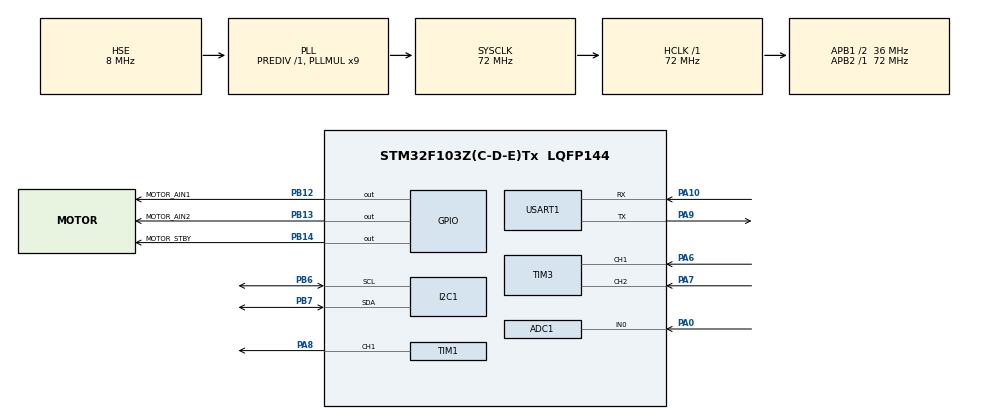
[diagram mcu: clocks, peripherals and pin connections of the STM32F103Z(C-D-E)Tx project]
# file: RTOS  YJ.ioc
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ADC1.Channel-0\#ChannelRegularConversion=ADC_CHANNEL_0
ADC1.ContinuousConvMode=ENABLE
ADC1.NbrOfConversionFlag=1
ADC1.Rank-0\#ChannelRegularConversion=1
ADC1.SamplingTime-0\#ChannelRegularConversion=ADC_SAMPLETIME_1CYCLE_5
ADC1.master=1
Dma.Request0=USART1_TX
Dma.Request1=USART1_RX
Dma.USART1_RX.1.Direction=DMA_PERIPH_TO_MEMORY
Dma.USART1_RX.1.Instance=DMA1_Channel5
Dma.USART1_RX.1.MemDataAlignment=DMA_MDATAALIGN_BYTE
Dma.USART1_RX.1.MemInc=DMA_MINC_ENABLE
Dma.USART1_RX.1.Mode=DMA_CIRCULAR
Dma.USART1_RX.1.PeriphDataAlignment=DMA_PDATAALIGN_BYTE
Dma.USART1_RX.1.PeriphInc=DMA_PINC_DISABLE
Dma.USART1_RX.1.Priority=DMA_PRIORITY_LOW
Dma.USART1_TX.0.Direction=DMA_MEMORY_TO_PERIPH
Dma.USART1_TX.0.Instance=DMA1_Channel4
Dma.USART1_TX.0.MemDataAlignment=DMA_MDATAALIGN_BYTE
Dma.USART1_TX.0.MemInc=DMA_MINC_ENABLE
Dma.USART1_TX.0.Mode=DMA_NORMAL
Dma.USART1_TX.0.PeriphDataAlignment=DMA_PDATAALIGN_BYTE
Dma.USART1_TX.0.PeriphInc=DMA_PINC_DISABLE
Dma.USART1_TX.0.Priority=DMA_PRIORITY_LOW
FREERTOS.Tasks01=defaultTask,0,128,StartDefaultTask,Default,NULL,Dynamic,NULL,NULL
FREERTOS.configCHECK_FOR_STACK_OVERFLOW=2
FREERTOS.configLIBRARY_MAX_SYSCALL_INTERRUPT_PRIORITY=6
FREERTOS.configMAX_PRIORITIES=8
FREERTOS.configTOTAL_HEAP_SIZE=16384
FREERTOS.configUSE_COUNTING_SEMAPHORES=1
I2C1.I2C_Mode=I2C_Fast
Mcu.Family=STM32F1
Mcu.Name=STM32F103Z(C-D-E)Tx
Mcu.Package=LQFP144
NVIC.DMA1_Channel4_IRQn=true\:6\:0\:true\:false\:true\:true\:false\:true\:true
NVIC.DMA1_Channel5_IRQn=true\:6\:0\:true\:false\:true\:true\:false\:true\:true
NVIC.PriorityGroup=NVIC_PRIORITYGROUP_4
NVIC.TIM2_IRQn=true\:6\:0\:true\:false\:true\:true\:true\:true\:true
NVIC.TIM4_IRQn=true\:15\:0\:false\:false\:true\:false\:false\:true\:true
NVIC.TimeBase=TIM4_IRQn
NVIC.TimeBaseIP=TIM4
NVIC.USART1_IRQn=true\:6\:0\:true\:false\:true\:true\:false\:true\:true
OSC_IN.Mode=HSE-External-Oscillator
OSC_IN.Signal=RCC_OSC_IN
OSC_OUT.Mode=HSE-External-Oscillator
OSC_OUT.Signal=RCC_OSC_OUT
PA0-WKUP.Signal=ADCx_IN0
PA10.Mode=Asynchronous
PA10.Signal=USART1_RX
PA13.Mode=Serial_Wire
PA13.Signal=SYS_JTMS-SWDIO
PA14.Mode=Serial_Wire
PA14.Signal=SYS_JTCK-SWCLK
PA6.Signal=S_TIM3_CH1
PA7.Signal=S_TIM3_CH2
PA8.Signal=S_TIM1_CH1
PA9.Mode=Asynchronous
PA9.Signal=USART1_TX
PB12.GPIO_Label=MOTOR_AIN1
PB12.Signal=GPIO_Output
PB13.GPIO_Label=MOTOR_AIN2
PB13.Signal=GPIO_Output
PB14.GPIO_Label=MOTOR_STBY
PB14.Signal=GPIO_Output
PB6.Mode=I2C
PB6.Signal=I2C1_SCL
PB7.Mode=I2C
PB7.Signal=I2C1_SDA
PC14-OSC32_IN.Mode=LSE-External-Oscillator
PC14-OSC32_IN.Signal=RCC_OSC32_IN
PC15-OSC32_OUT.Mode=LSE-External-Oscillator
PC15-OSC32_OUT.Signal=RCC_OSC32_OUT
ProjectManager.HeapSize=0x200
ProjectManager.StackSize=0x400
ProjectManager.TargetToolchain=MDK-ARM V5.32
RCC.ADCPresc=RCC_ADCPCLK2_DIV6
RCC.AHBFreq_Value=72000000
RCC.APB1CLKDivider=RCC_HCLK_DIV2
RCC.APB1Freq_Value=36000000
RCC.APB1TimFreq_Value=72000000
RCC.APB2Freq_Value=72000000
RCC.APB2TimFreq_Value=72000000
RCC.HCLKFreq_Value=72000000
RCC.PLLMUL=RCC_PLL_MUL9
RCC.PLLSourceVirtual=RCC_PLLSOURCE_HSE
RCC.SYSCLKFreq_VALUE=72000000
RCC.SYSCLKSource=RCC_SYSCLKSOURCE_PLLCLK
RCC.USBFreq_Value=72000000
SH.ADCx_IN0.0=ADC1_IN0,IN0
SH.S_TIM1_CH1.0=TIM1_CH1,PWM Generation1 CH1
SH.S_TIM3_CH1.0=TIM3_CH1,Encoder_Interface
SH.S_TIM3_CH2.0=TIM3_CH2,Encoder_Interface
TIM1.Channel-PWM\ Generation1\ CH1=TIM_CHANNEL_1
TIM1.Period=999
TIM1.Prescaler=3
TIM2.Period=999
TIM2.Prescaler=71
TIM3.EncoderMode=TIM_ENCODERMODE_TI12
USART1.VirtualMode=VM_ASYNC
VP_FREERTOS_VS_CMSIS_V1.Mode=CMSIS_V1
VP_SYS_VS_tim4.Mode=TIM4
VP_TIM2_VS_ClockSourceINT.Mode=Internal
board=custom

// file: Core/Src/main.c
/* USER CODE BEGIN Header */
/**
  ******************************************************************************
  * @file           : main.c
  * @brief          : Main program body
  ******************************************************************************
  * @attention
  *
  * Copyright (c) 2026 STMicroelectronics.
  * All rights reserved.
  *
  * This software is licensed under terms that can be found in the LICENSE file
  * in the root directory of this software component.
  * If no LICENSE file comes with this software, it is provided AS-IS.
  *
  ******************************************************************************
  */
/* USER CODE END Header */
#include "main.h"
#include "FreeRTOS.h"
#include "task.h"
#include "cmsis_os.h"
#include "tasks.h"
#include "uart_dma.h"
#include "adc.h"
#include "dma.h"
#include "i2c.h"
#include "tim.h"
#include "usart.h"
#include "gpio.h"

void SystemClock_Config(void);
/* USER CODE BEGIN PFP */
void MX_FREERTOS_Init(void);
/* USER CODE END PFP */

int main(void)
{

  /* MCU Configuration--------------------------------------------------------*/

  /* Reset of all peripherals, Initializes the Flash interface and the Systick. */
  HAL_Init();

  /* Configure the system clock */
  SystemClock_Config();

  /* Initialize all configured peripherals */
  MX_GPIO_Init();
  MX_DMA_Init();
  MX_USART1_UART_Init();
  MX_ADC1_Init();
  MX_I2C1_Init();
  MX_TIM1_Init();
  MX_TIM2_Init();
  MX_TIM3_Init();
  /* USER CODE BEGIN 2 */
  uart_dma_init();
  /* USER CODE END 2 */

  /* Init FreeRTOS (creates the tasks) */
  MX_FREERTOS_Init();

  /* Start the scheduler (never returns) */
  osKernelStart();

  /* We should never get here as control is now taken by the scheduler */

  /* Infinite loop */
  while (1)
  {

  }
}

void SystemClock_Config(void)
{
  RCC_OscInitTypeDef RCC_OscInitStruct = {0};
  RCC_ClkInitTypeDef RCC_ClkInitStruct = {0};
  RCC_PeriphCLKInitTypeDef PeriphClkInit = {0};

  /** Initializes the RCC Oscillators according to the specified parameters
  * in the RCC_OscInitTypeDef structure.
  */
  RCC_OscInitStruct.OscillatorType = RCC_OSCILLATORTYPE_HSE;
  RCC_OscInitStruct.HSEState = RCC_HSE_ON;
  RCC_OscInitStruct.HSEPredivValue = RCC_HSE_PREDIV_DIV1;
  RCC_OscInitStruct.HSIState = RCC_HSI_ON;
  RCC_OscInitStruct.PLL.PLLState = RCC_PLL_ON;
  RCC_OscInitStruct.PLL.PLLSource = RCC_PLLSOURCE_HSE;
  RCC_OscInitStruct.PLL.PLLMUL = RCC_PLL_MUL9;
  if (HAL_RCC_OscConfig(&RCC_OscInitStruct) != HAL_OK)
  {
    Error_Handler();
  }

  /** Initializes the CPU, AHB and APB buses clocks
  */
  RCC_ClkInitStruct.ClockType = RCC_CLOCKTYPE_HCLK|RCC_CLOCKTYPE_SYSCLK
                              |RCC_CLOCKTYPE_PCLK1|RCC_CLOCKTYPE_PCLK2;
  RCC_ClkInitStruct.SYSCLKSource = RCC_SYSCLKSOURCE_PLLCLK;
  RCC_ClkInitStruct.AHBCLKDivider = RCC_SYSCLK_DIV1;
  RCC_ClkInitStruct.APB1CLKDivider = RCC_HCLK_DIV2;
  RCC_ClkInitStruct.APB2CLKDivider = RCC_HCLK_DIV1;

  if (HAL_RCC_ClockConfig(&RCC_ClkInitStruct, FLASH_LATENCY_2) != HAL_OK)
  {
    Error_Handler();
  }
  PeriphClkInit.PeriphClockSelection = RCC_PERIPHCLK_ADC;
  PeriphClkInit.AdcClockSelection = RCC_ADCPCLK2_DIV6;
  if (HAL_RCCEx_PeriphCLKConfig(&PeriphClkInit) != HAL_OK)
  {
    Error_Handler();
  }
}

void HAL_TIM_PeriodElapsedCallback(TIM_HandleTypeDef *htim)
{
  if (htim->Instance == TIM4)
  {
    HAL_IncTick();
  }
}

void Error_Handler(void)
{
  __disable_irq();
  while (1)
  {
  }
}

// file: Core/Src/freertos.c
/* USER CODE BEGIN Header */
/**
  ******************************************************************************
  * File Name          : freertos.c
  * Description        : Code for freertos applications
  ******************************************************************************
  */
/* USER CODE END Header */

#include "FreeRTOS.h"
#include "task.h"
#include "main.h"
#include "cmsis_os.h"

/* USER CODE BEGIN Includes */
#include "tasks.h"
/* USER CODE END Includes */

osThreadId defaultTaskHandle;

void StartDefaultTask(void const * argument);

void MX_FREERTOS_Init(void); /* (MISRA C 2004 rule 8.1) */

/* GetIdleTaskMemory prototype (linked to static allocation support) */
void vApplicationGetIdleTaskMemory( StaticTask_t **ppxIdleTaskTCBBuffer, StackType_t **ppxIdleTaskStackBuffer, uint32_t *pulIdleTaskStackSize );

/* Hook prototypes */
void vApplicationStackOverflowHook(xTaskHandle xTask, signed char *pcTaskName);

/* USER CODE BEGIN 4 */
__weak void vApplicationStackOverflowHook(xTaskHandle xTask, signed char *pcTaskName)
{
   /* Run time stack overflow checking is performed if
   configCHECK_FOR_STACK_OVERFLOW is defined to 1 or 2. This hook function is
   called if a stack overflow is detected. */
   (void)xTask;
   (void)pcTaskName;
   taskDISABLE_INTERRUPTS();
   for (;;);
}
/* USER CODE END 4 */

/* USER CODE BEGIN GET_IDLE_TASK_MEMORY */
static StaticTask_t xIdleTaskTCBBuffer;
static StackType_t xIdleStack[configMINIMAL_STACK_SIZE];

void vApplicationGetIdleTaskMemory( StaticTask_t **ppxIdleTaskTCBBuffer, StackType_t **ppxIdleTaskStackBuffer, uint32_t *pulIdleTaskStackSize )
{
  *ppxIdleTaskTCBBuffer = &xIdleTaskTCBBuffer;
  *ppxIdleTaskStackBuffer = &xIdleStack[0];
  *pulIdleTaskStackSize = configMINIMAL_STACK_SIZE;
  /* place for user code */
}
/* USER CODE END GET_IDLE_TASK_MEMORY */

void MX_FREERTOS_Init(void) {

  /* Create the thread(s) */
  /* definition and creation of defaultTask */
  osThreadDef(defaultTask, StartDefaultTask, osPriorityNormal, 0, 128);
  defaultTaskHandle = osThreadCreate(osThread(defaultTask), NULL);

  /* USER CODE BEGIN RTOS_THREADS */
  /* add threads, ... */
  /* 创建油烟机 7 个任务（原生 xTaskCreate，见 APP/tasks.c） */
  tasks_init();
  /* USER CODE END RTOS_THREADS */
}

void StartDefaultTask(void const * argument)
{
  /* USER CODE BEGIN StartDefaultTask */
  /* Infinite loop */
  /* 业务都在 APP/tasks.c 的 7 个任务里，defaultTask 这里空转即可 */
  for(;;)
  {
    osDelay(1);
  }
  /* USER CODE END StartDefaultTask */
}
